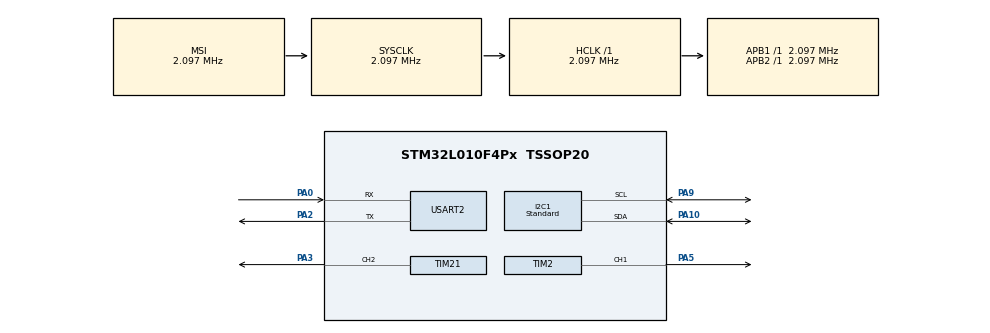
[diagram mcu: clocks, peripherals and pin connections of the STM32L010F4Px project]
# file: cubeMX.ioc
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I2C1.I2C_Speed_Mode=I2C_Standard
I2C1.Timing=0x00000608
Mcu.Family=STM32L0
Mcu.Name=STM32L010F4Px
Mcu.Package=TSSOP20
PA0-CK_IN.Mode=Asynchronous
PA0-CK_IN.Signal=USART2_RX
PA10.Mode=I2C
PA10.Signal=I2C1_SDA
PA13.Mode=Serial_Wire
PA13.Signal=SYS_SWDIO
PA14.Mode=Serial_Wire
PA14.Signal=SYS_SWCLK
PA2.Mode=Asynchronous
PA2.Signal=USART2_TX
PA3.Signal=S_TIM21_CH2
PA5.Signal=S_TIM2_CH1
PA9.Mode=I2C
PA9.Signal=I2C1_SCL
ProjectManager.HeapSize=0x200
ProjectManager.StackSize=0x400
ProjectManager.TargetToolchain=CMake
RCC.AHBFreq_Value=2097000
RCC.APB1Freq_Value=2097000
RCC.APB1TimFreq_Value=2097000
RCC.APB2Freq_Value=2097000
RCC.APB2TimFreq_Value=2097000
RCC.HSE_VALUE=8000000
RCC.HSI16_VALUE=16000000
RCC.HSI_VALUE=16000000
RCC.LSE_VALUE=32768
RCC.MSI_VALUE=2097000
RCC.SYSCLKFreq_VALUE=2097000
RCC.VCOOutputFreq_Value=48000000
SH.S_TIM21_CH2.0=TIM21_CH2,PWM Generation2 CH2
SH.S_TIM2_CH1.0=TIM2_CH1,PWM Generation1 CH1
TIM2.Channel-PWM\ Generation1\ CH1=TIM_CHANNEL_1
TIM21.Channel-PWM\ Generation2\ CH2=TIM_CHANNEL_2
USART2.VirtualMode-Asynchronous=VM_ASYNC
VP_TIM21_VS_ClockSourceINT.Mode=Internal
VP_TIM2_VS_ClockSourceINT.Mode=Internal
board=custom

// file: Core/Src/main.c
/* USER CODE BEGIN Header */
/**
  ******************************************************************************
  * @file           : main.c
  * @brief          : Main program body
  ******************************************************************************
  * @attention
  *
  * Copyright (c) 2026 STMicroelectronics.
  * All rights reserved.
  *
  * This software is licensed under terms that can be found in the LICENSE file
  * in the root directory of this software component.
  * If no LICENSE file comes with this software, it is provided AS-IS.
  *
  ******************************************************************************
  */
/* USER CODE END Header */
#include "main.h"

I2C_HandleTypeDef hi2c1;

TIM_HandleTypeDef htim2;
TIM_HandleTypeDef htim21;

UART_HandleTypeDef huart2;

void SystemClock_Config(void);
static void MX_GPIO_Init(void);
static void MX_I2C1_Init(void);
static void MX_TIM2_Init(void);
static void MX_TIM21_Init(void);
static void MX_USART2_UART_Init(void);
/* USER CODE BEGIN PFP */

#ifdef __cplusplus
  extern "C" {
#endif

void CTRL_application_main(void);

#ifdef __cplusplus
  }
#endif

/* USER CODE END PFP */

int main(void)
{

  /* MCU Configuration--------------------------------------------------------*/

  /* Reset of all peripherals, Initializes the Flash interface and the Systick. */
  HAL_Init();

  /* Configure the system clock */
  SystemClock_Config();

  /* Initialize all configured peripherals */
  MX_GPIO_Init();
  MX_I2C1_Init();
  MX_TIM2_Init();
  MX_TIM21_Init();
  MX_USART2_UART_Init();
  /* USER CODE BEGIN 2 */

  CTRL_application_main();

  /* USER CODE END 2 */

  /* Infinite loop */
  /* USER CODE BEGIN WHILE */
  while (0)     // dont need this, all handled in application::main
  {
    /* USER CODE END WHILE */

  }
}

void SystemClock_Config(void)
{
  RCC_OscInitTypeDef RCC_OscInitStruct = {0};
  RCC_ClkInitTypeDef RCC_ClkInitStruct = {0};
  RCC_PeriphCLKInitTypeDef PeriphClkInit = {0};

  /** Configure the main internal regulator output voltage
  */
  __HAL_PWR_VOLTAGESCALING_CONFIG(PWR_REGULATOR_VOLTAGE_SCALE1);

  /** Initializes the RCC Oscillators according to the specified parameters
  * in the RCC_OscInitTypeDef structure.
  */
  RCC_OscInitStruct.OscillatorType = RCC_OSCILLATORTYPE_MSI;
  RCC_OscInitStruct.MSIState = RCC_MSI_ON;
  RCC_OscInitStruct.MSICalibrationValue = 0;
  RCC_OscInitStruct.MSIClockRange = RCC_MSIRANGE_5;
  RCC_OscInitStruct.PLL.PLLState = RCC_PLL_NONE;
  if (HAL_RCC_OscConfig(&RCC_OscInitStruct) != HAL_OK)
  {
    Error_Handler();
  }

  /** Initializes the CPU, AHB and APB buses clocks
  */
  RCC_ClkInitStruct.ClockType = RCC_CLOCKTYPE_HCLK|RCC_CLOCKTYPE_SYSCLK
                              |RCC_CLOCKTYPE_PCLK1|RCC_CLOCKTYPE_PCLK2;
  RCC_ClkInitStruct.SYSCLKSource = RCC_SYSCLKSOURCE_MSI;
  RCC_ClkInitStruct.AHBCLKDivider = RCC_SYSCLK_DIV1;
  RCC_ClkInitStruct.APB1CLKDivider = RCC_HCLK_DIV1;
  RCC_ClkInitStruct.APB2CLKDivider = RCC_HCLK_DIV1;

  if (HAL_RCC_ClockConfig(&RCC_ClkInitStruct, FLASH_LATENCY_0) != HAL_OK)
  {
    Error_Handler();
  }
  PeriphClkInit.PeriphClockSelection = RCC_PERIPHCLK_USART2|RCC_PERIPHCLK_I2C1;
  PeriphClkInit.Usart2ClockSelection = RCC_USART2CLKSOURCE_PCLK1;
  PeriphClkInit.I2c1ClockSelection = RCC_I2C1CLKSOURCE_PCLK1;
  if (HAL_RCCEx_PeriphCLKConfig(&PeriphClkInit) != HAL_OK)
  {
    Error_Handler();
  }
}

static void MX_I2C1_Init(void)
{

  hi2c1.Instance = I2C1;
  hi2c1.Init.Timing = 0x00000608;
  hi2c1.Init.OwnAddress1 = 0;
  hi2c1.Init.AddressingMode = I2C_ADDRESSINGMODE_7BIT;
  hi2c1.Init.DualAddressMode = I2C_DUALADDRESS_DISABLE;
  hi2c1.Init.OwnAddress2 = 0;
  hi2c1.Init.OwnAddress2Masks = I2C_OA2_NOMASK;
  hi2c1.Init.GeneralCallMode = I2C_GENERALCALL_DISABLE;
  hi2c1.Init.NoStretchMode = I2C_NOSTRETCH_DISABLE;
  if (HAL_I2C_Init(&hi2c1) != HAL_OK)
  {
    Error_Handler();
  }

  /** Configure Analogue filter
  */
  if (HAL_I2CEx_ConfigAnalogFilter(&hi2c1, I2C_ANALOGFILTER_ENABLE) != HAL_OK)
  {
    Error_Handler();
  }

  /** Configure Digital filter
  */
  if (HAL_I2CEx_ConfigDigitalFilter(&hi2c1, 0) != HAL_OK)
  {
    Error_Handler();
  }

}

static void MX_TIM2_Init(void)
{

  TIM_ClockConfigTypeDef sClockSourceConfig = {0};
  TIM_MasterConfigTypeDef sMasterConfig = {0};
  TIM_OC_InitTypeDef sConfigOC = {0};

  htim2.Instance = TIM2;
  htim2.Init.Prescaler = 0;
  htim2.Init.CounterMode = TIM_COUNTERMODE_UP;
  htim2.Init.Period = 65535;
  htim2.Init.ClockDivision = TIM_CLOCKDIVISION_DIV1;
  htim2.Init.AutoReloadPreload = TIM_AUTORELOAD_PRELOAD_DISABLE;
  if (HAL_TIM_Base_Init(&htim2) != HAL_OK)
  {
    Error_Handler();
  }
  sClockSourceConfig.ClockSource = TIM_CLOCKSOURCE_INTERNAL;
  if (HAL_TIM_ConfigClockSource(&htim2, &sClockSourceConfig) != HAL_OK)
  {
    Error_Handler();
  }
  if (HAL_TIM_PWM_Init(&htim2) != HAL_OK)
  {
    Error_Handler();
  }
  sMasterConfig.MasterOutputTrigger = TIM_TRGO_RESET;
  sMasterConfig.MasterSlaveMode = TIM_MASTERSLAVEMODE_DISABLE;
  if (HAL_TIMEx_MasterConfigSynchronization(&htim2, &sMasterConfig) != HAL_OK)
  {
    Error_Handler();
  }
  sConfigOC.OCMode = TIM_OCMODE_PWM1;
  sConfigOC.Pulse = 0;
  sConfigOC.OCPolarity = TIM_OCPOLARITY_HIGH;
  sConfigOC.OCFastMode = TIM_OCFAST_DISABLE;
  if (HAL_TIM_PWM_ConfigChannel(&htim2, &sConfigOC, TIM_CHANNEL_1) != HAL_OK)
  {
    Error_Handler();
  }
  HAL_TIM_MspPostInit(&htim2);

}

static void MX_TIM21_Init(void)
{

  TIM_ClockConfigTypeDef sClockSourceConfig = {0};
  TIM_MasterConfigTypeDef sMasterConfig = {0};
  TIM_OC_InitTypeDef sConfigOC = {0};

  htim21.Instance = TIM21;
  htim21.Init.Prescaler = 0;
  htim21.Init.CounterMode = TIM_COUNTERMODE_UP;
  htim21.Init.Period = 65535;
  htim21.Init.ClockDivision = TIM_CLOCKDIVISION_DIV1;
  htim21.Init.AutoReloadPreload = TIM_AUTORELOAD_PRELOAD_DISABLE;
  if (HAL_TIM_Base_Init(&htim21) != HAL_OK)
  {
    Error_Handler();
  }
  sClockSourceConfig.ClockSource = TIM_CLOCKSOURCE_INTERNAL;
  if (HAL_TIM_ConfigClockSource(&htim21, &sClockSourceConfig) != HAL_OK)
  {
    Error_Handler();
  }
  if (HAL_TIM_PWM_Init(&htim21) != HAL_OK)
  {
    Error_Handler();
  }
  sMasterConfig.MasterOutputTrigger = TIM_TRGO_RESET;
  sMasterConfig.MasterSlaveMode = TIM_MASTERSLAVEMODE_DISABLE;
  if (HAL_TIMEx_MasterConfigSynchronization(&htim21, &sMasterConfig) != HAL_OK)
  {
    Error_Handler();
  }
  sConfigOC.OCMode = TIM_OCMODE_PWM1;
  sConfigOC.Pulse = 0;
  sConfigOC.OCPolarity = TIM_OCPOLARITY_HIGH;
  sConfigOC.OCFastMode = TIM_OCFAST_DISABLE;
  if (HAL_TIM_PWM_ConfigChannel(&htim21, &sConfigOC, TIM_CHANNEL_2) != HAL_OK)
  {
    Error_Handler();
  }
  HAL_TIM_MspPostInit(&htim21);

}

static void MX_USART2_UART_Init(void)
{

  huart2.Instance = USART2;
  huart2.Init.BaudRate = 115200;
  huart2.Init.WordLength = UART_WORDLENGTH_8B;
  huart2.Init.StopBits = UART_STOPBITS_1;
  huart2.Init.Parity = UART_PARITY_NONE;
  huart2.Init.Mode = UART_MODE_TX_RX;
  huart2.Init.HwFlowCtl = UART_HWCONTROL_NONE;
  huart2.Init.OverSampling = UART_OVERSAMPLING_16;
  huart2.Init.OneBitSampling = UART_ONE_BIT_SAMPLE_DISABLE;
  huart2.AdvancedInit.AdvFeatureInit = UART_ADVFEATURE_NO_INIT;
  if (HAL_UART_Init(&huart2) != HAL_OK)
  {
    Error_Handler();
  }

}

static void MX_GPIO_Init(void)
{

  /* GPIO Ports Clock Enable */
  __HAL_RCC_GPIOA_CLK_ENABLE();

}

void Error_Handler(void)
{
  __disable_irq();
  while (1)
  {
  }
}
